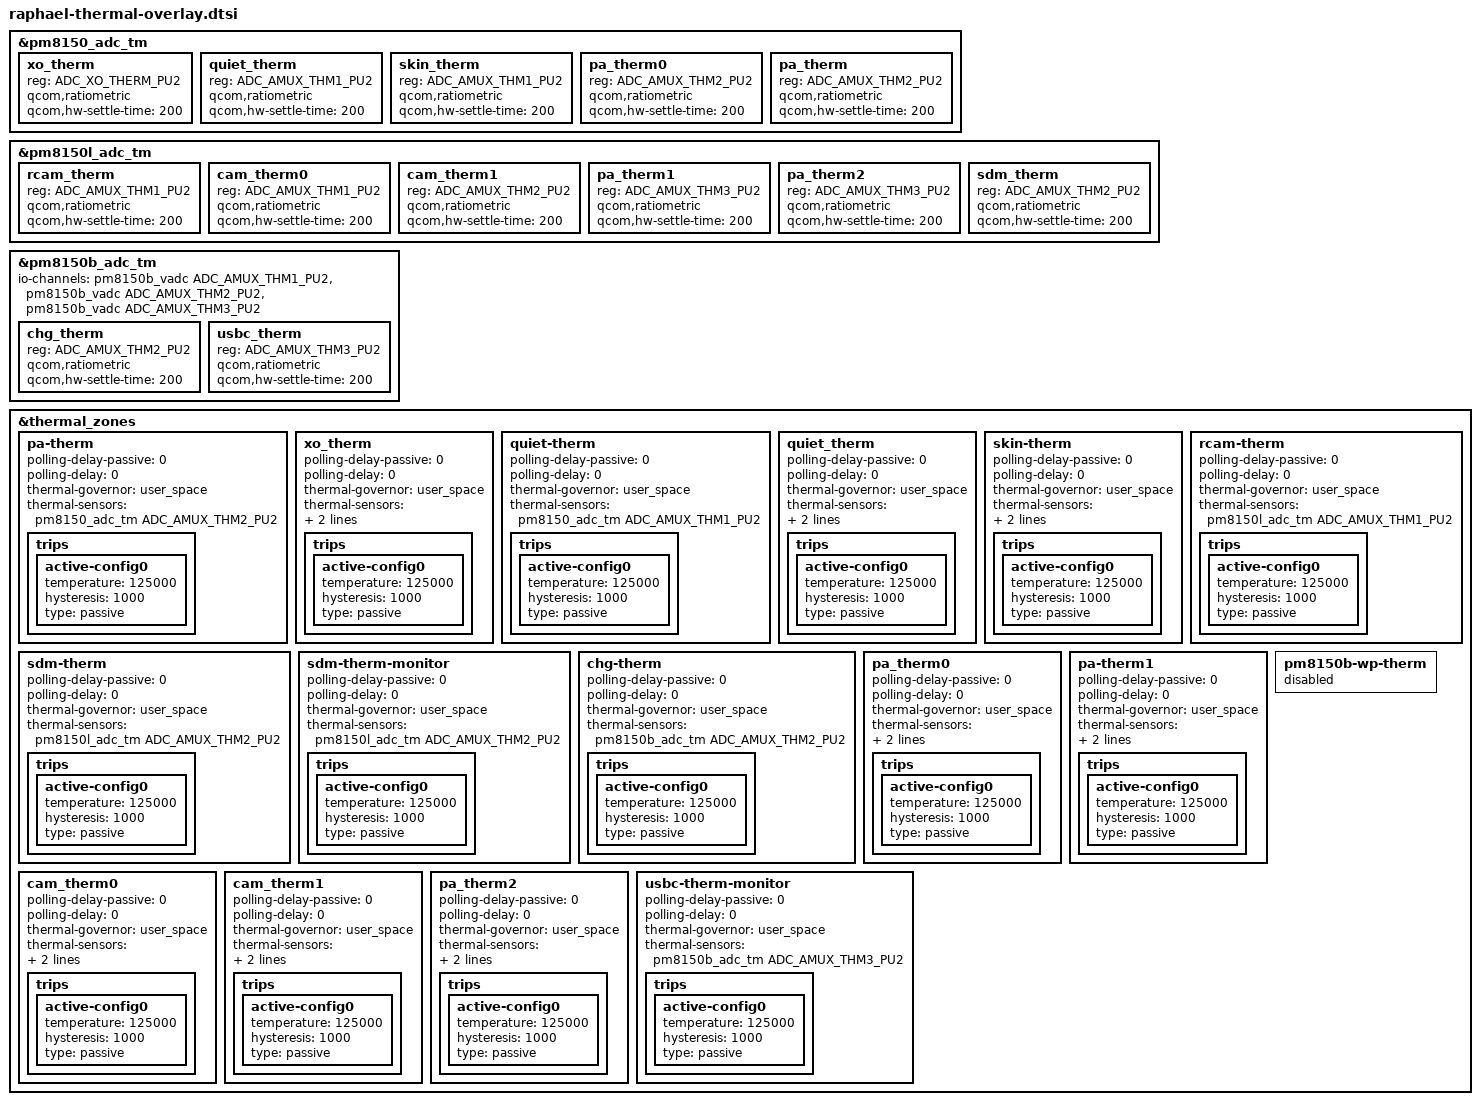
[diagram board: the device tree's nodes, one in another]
/* Copyright (c) 2020, The Linux Foundation. All rights reserved.
 *
 * This program is free software; you can redistribute it and/or modify
 * it under the terms of the GNU General Public License version 2 and
 * only version 2 as published by the Free Software Foundation.
 *
 * This program is distributed in the hope that it will be useful,
 * but WITHOUT ANY WARRANTY; without even the implied warranty of
 * MERCHANTABILITY or FITNESS FOR A PARTICULAR PURPOSE.  See the
 * GNU General Public License for more details.
 */

&pm8150_adc_tm {
	xo_therm {
		reg = <ADC_XO_THERM_PU2>;
		qcom,ratiometric;
		qcom,hw-settle-time = <200>;
	};

	quiet_therm {
		reg = <ADC_AMUX_THM1_PU2>;
		qcom,ratiometric;
		qcom,hw-settle-time = <200>;
	};

	skin_therm {
		reg = <ADC_AMUX_THM1_PU2>;
		qcom,ratiometric;
		qcom,hw-settle-time = <200>;
	};

	pa_therm0 {
		reg = <ADC_AMUX_THM2_PU2>;
		qcom,ratiometric;
		qcom,hw-settle-time = <200>;
	};

	pa_therm {
		reg = <ADC_AMUX_THM2_PU2>;
		qcom,ratiometric;
		qcom,hw-settle-time = <200>;
	};
};

&pm8150l_adc_tm {
	rcam_therm {
		reg = <ADC_AMUX_THM1_PU2>;
		qcom,ratiometric;
		qcom,hw-settle-time = <200>;
	};

	cam_therm0 {
		reg = <ADC_AMUX_THM1_PU2>;
		qcom,ratiometric;
		qcom,hw-settle-time = <200>;
	};

	cam_therm1 {
		reg = <ADC_AMUX_THM2_PU2>;
		qcom,ratiometric;
		qcom,hw-settle-time = <200>;
	};

	pa_therm1 {
		reg = <ADC_AMUX_THM3_PU2>;
		qcom,ratiometric;
		qcom,hw-settle-time = <200>;
	};

	pa_therm2 {
		reg = <ADC_AMUX_THM3_PU2>;
		qcom,ratiometric;
		qcom,hw-settle-time = <200>;
	};

	sdm_therm {
		reg = <ADC_AMUX_THM2_PU2>;
		qcom,ratiometric;
		qcom,hw-settle-time = <200>;
	};
};

&pm8150b_adc_tm {
        io-channels = <&pm8150b_vadc ADC_AMUX_THM1_PU2>,
                      <&pm8150b_vadc ADC_AMUX_THM2_PU2>,
                      <&pm8150b_vadc ADC_AMUX_THM3_PU2>;

	chg_therm {
		reg = <ADC_AMUX_THM2_PU2>;
		qcom,ratiometric;
		qcom,hw-settle-time = <200>;
	};

	usbc_therm {
		reg = <ADC_AMUX_THM3_PU2>;
		qcom,ratiometric;
		qcom,hw-settle-time = <200>;
	};
};

&thermal_zones {
	pa-therm {
		polling-delay-passive = <0>;
		polling-delay = <0>;
		thermal-governor = "user_space";
		thermal-sensors = <&pm8150_adc_tm ADC_AMUX_THM2_PU2>;
		trips {
			active-config0 {
				temperature = <125000>;
				hysteresis = <1000>;
				type = "passive";
			};
		};
	};

	xo_therm {
		polling-delay-passive = <0>;
		polling-delay = <0>;
		thermal-governor = "user_space";
		thermal-sensors = <&pm8150_adc_tm ADC_XO_THERM_PU2>;
		wake-capable-sensor;
		trips {
			active-config0 {
				temperature = <125000>;
				hysteresis = <1000>;
				type = "passive";
			};
		};
	};

	quiet-therm {
		polling-delay-passive = <0>;
		polling-delay = <0>;
		thermal-governor = "user_space";
		thermal-sensors = <&pm8150_adc_tm ADC_AMUX_THM1_PU2>;
		trips {
			active-config0 {
				temperature = <125000>;
				hysteresis = <1000>;
				type = "passive";
			};
		};
	};

	quiet_therm {
		polling-delay-passive = <0>;
		polling-delay = <0>;
		thermal-governor = "user_space";
		thermal-sensors = <&pm8150_adc_tm ADC_AMUX_THM1_PU2>;
		wake-capable-sensor;
		trips {
			active-config0 {
				temperature = <125000>;
				hysteresis = <1000>;
				type = "passive";
			};
		};
	};

	skin-therm {
		polling-delay-passive = <0>;
		polling-delay = <0>;
		thermal-governor = "user_space";
		thermal-sensors = <&pm8150_adc_tm ADC_AMUX_THM1_PU2>;
		wake-capable-sensor;
		trips {
			active-config0 {
				temperature = <125000>;
				hysteresis = <1000>;
				type = "passive";
			};
		};
	};

	rcam-therm {
		polling-delay-passive = <0>;
		polling-delay = <0>;
		thermal-governor = "user_space";
		thermal-sensors = <&pm8150l_adc_tm ADC_AMUX_THM1_PU2>;
		trips {
			active-config0 {
				temperature = <125000>;
				hysteresis = <1000>;
				type = "passive";
			};
		};
	};

	sdm-therm {
		polling-delay-passive = <0>;
		polling-delay = <0>;
		thermal-governor = "user_space";
		thermal-sensors = <&pm8150l_adc_tm ADC_AMUX_THM2_PU2>;
		trips {
			active-config0 {
				temperature = <125000>;
				hysteresis = <1000>;
				type = "passive";
			};
		};
	};

	sdm-therm-monitor {
		polling-delay-passive = <0>;
		polling-delay = <0>;
		thermal-governor = "user_space";
		thermal-sensors = <&pm8150l_adc_tm ADC_AMUX_THM2_PU2>;
		trips {
			active-config0 {
				temperature = <125000>;
				hysteresis = <1000>;
				type = "passive";
			};
		};
	};

	chg-therm {
		polling-delay-passive = <0>;
		polling-delay = <0>;
		thermal-governor = "user_space";
		thermal-sensors = <&pm8150b_adc_tm ADC_AMUX_THM2_PU2>;
		trips {
			active-config0 {
				temperature = <125000>;
				hysteresis = <1000>;
				type = "passive";
			};
		};
	};

	pa_therm0 {
		polling-delay-passive = <0>;
		polling-delay = <0>;
		thermal-governor = "user_space";
		thermal-sensors = <&pm8150_adc_tm ADC_AMUX_THM2_PU2>;
		wake-capable-sensor;
		trips {
			active-config0 {
				temperature = <125000>;
				hysteresis = <1000>;
				type = "passive";
			};
		};
	};

	pa-therm1 {
		polling-delay-passive = <0>;
		polling-delay = <0>;
		thermal-governor = "user_space";
		thermal-sensors = <&pm8150_adc_tm ADC_AMUX_THM2_PU2>;
		wake-capable-sensor;
		trips {
			active-config0 {
				temperature = <125000>;
				hysteresis = <1000>;
				type = "passive";
			};
		};
	};

	cam_therm0 {
		polling-delay-passive = <0>;
		polling-delay = <0>;
		thermal-governor = "user_space";
		thermal-sensors = <&pm8150l_adc_tm ADC_AMUX_THM1_PU2>;
		wake-capable-sensor;
		trips {
			active-config0 {
				temperature = <125000>;
				hysteresis = <1000>;
				type = "passive";
			};
		};
	};

	cam_therm1 {
		polling-delay-passive = <0>;
		polling-delay = <0>;
		thermal-governor = "user_space";
		thermal-sensors = <&pm8150l_adc_tm ADC_AMUX_THM2_PU2>;
		wake-capable-sensor;
		trips {
			active-config0 {
				temperature = <125000>;
				hysteresis = <1000>;
				type = "passive";
			};
		};
	};

	pa_therm2 {
		polling-delay-passive = <0>;
		polling-delay = <0>;
		thermal-governor = "user_space";
		thermal-sensors = <&pm8150l_adc_tm ADC_AMUX_THM3_PU2>;
		wake-capable-sensor;
		trips {
			active-config0 {
				temperature = <125000>;
				hysteresis = <1000>;
				type = "passive";
			};
		};
	};

	usbc-therm-monitor {
		polling-delay-passive = <0>;
		polling-delay = <0>;
		thermal-governor = "user_space";
		thermal-sensors = <&pm8150b_adc_tm ADC_AMUX_THM3_PU2>;
		trips {
			active-config0 {
				temperature = <125000>;
				hysteresis = <1000>;
				type = "passive";
			};
		};
	};

	pm8150b-wp-therm {
		status = "disabled";
	};
};
